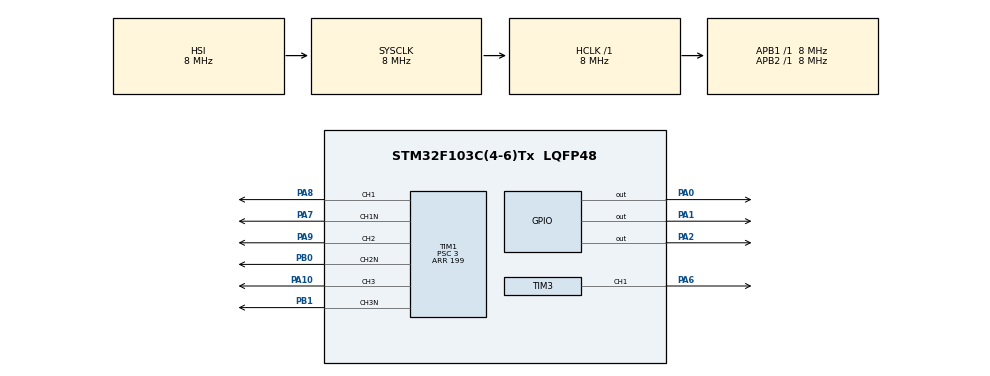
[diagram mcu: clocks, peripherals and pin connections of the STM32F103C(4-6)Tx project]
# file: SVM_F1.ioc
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Mcu.Family=STM32F1
Mcu.Name=STM32F103C(4-6)Tx
Mcu.Package=LQFP48
NVIC.PriorityGroup=NVIC_PRIORITYGROUP_4
PA0-WKUP.Signal=GPIO_Output
PA1.Signal=GPIO_Output
PA10.Signal=S_TIM1_CH3
PA2.Signal=GPIO_Output
PA6.Signal=S_TIM3_CH1
PA7.Mode=PWM Generation1 CH1 CH1N
PA7.Signal=TIM1_CH1N
PA8.Signal=S_TIM1_CH1
PA9.Signal=S_TIM1_CH2
PB0.Mode=PWM Generation2 CH2 CH2N
PB0.Signal=TIM1_CH2N
PB1.Mode=PWM Generation3 CH3 CH3N
PB1.Signal=TIM1_CH3N
ProjectManager.HeapSize=0x200
ProjectManager.StackSize=0x400
ProjectManager.TargetToolchain=TrueSTUDIO
RCC.AHBFreq_Value=8000000
RCC.APB1Freq_Value=8000000
RCC.APB1TimFreq_Value=8000000
RCC.APB2Freq_Value=8000000
RCC.APB2TimFreq_Value=8000000
RCC.HCLKFreq_Value=8000000
RCC.SYSCLKFreq_VALUE=8000000
RCC.USBFreq_Value=8000000
SH.S_TIM1_CH1.0=TIM1_CH1,PWM Generation1 CH1 CH1N
SH.S_TIM1_CH2.0=TIM1_CH2,PWM Generation2 CH2 CH2N
SH.S_TIM1_CH3.0=TIM1_CH3,PWM Generation3 CH3 CH3N
SH.S_TIM3_CH1.0=TIM3_CH1,PWM Generation1 CH1
TIM1.Channel-PWM\ Generation1\ CH1\ CH1N=TIM_CHANNEL_1
TIM1.Channel-PWM\ Generation2\ CH2\ CH2N=TIM_CHANNEL_2
TIM1.Channel-PWM\ Generation3\ CH3\ CH3N=TIM_CHANNEL_3
TIM1.Period=199
TIM1.Prescaler=3
TIM3.Channel-PWM\ Generation1\ CH1=TIM_CHANNEL_1
TIM3.Period=199
TIM3.Prescaler=3
VP_SYS_VS_ND.Mode=No_Debug
VP_TIM1_VS_ClockSourceINT.Mode=Internal
VP_TIM3_VS_ClockSourceINT.Mode=Internal
board=custom

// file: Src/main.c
/**
  ******************************************************************************
  * @file           : main.c
  * @brief          : Main program body
  ******************************************************************************
  ** This notice applies to any and all portions of this file
  * that are not between comment pairs USER CODE BEGIN and
  * USER CODE END. Other portions of this file, whether
  * inserted by the user or by software development tools
  * are owned by their respective copyright owners.
  *
  * COPYRIGHT(c) 2018 STMicroelectronics
  *
  * Redistribution and use in source and binary forms, with or without modification,
  * are permitted provided that the following conditions are met:
  *   1. Redistributions of source code must retain the above copyright notice,
  *      this list of conditions and the following disclaimer.
  *   2. Redistributions in binary form must reproduce the above copyright notice,
  *      this list of conditions and the following disclaimer in the documentation
  *      and/or other materials provided with the distribution.
  *   3. Neither the name of STMicroelectronics nor the names of its contributors
  *      may be used to endorse or promote products derived from this software
  *      without specific prior written permission.
  *
  * THIS SOFTWARE IS PROVIDED BY THE COPYRIGHT HOLDERS AND CONTRIBUTORS "AS IS"
  * AND ANY EXPRESS OR IMPLIED WARRANTIES, INCLUDING, BUT NOT LIMITED TO, THE
  * IMPLIED WARRANTIES OF MERCHANTABILITY AND FITNESS FOR A PARTICULAR PURPOSE ARE
  * DISCLAIMED. IN NO EVENT SHALL THE COPYRIGHT HOLDER OR CONTRIBUTORS BE LIABLE
  * FOR ANY DIRECT, INDIRECT, INCIDENTAL, SPECIAL, EXEMPLARY, OR CONSEQUENTIAL
  * DAMAGES (INCLUDING, BUT NOT LIMITED TO, PROCUREMENT OF SUBSTITUTE GOODS OR
  * SERVICES; LOSS OF USE, DATA, OR PROFITS; OR BUSINESS INTERRUPTION) HOWEVER
  * CAUSED AND ON ANY THEORY OF LIABILITY, WHETHER IN CONTRACT, STRICT LIABILITY,
  * OR TORT (INCLUDING NEGLIGENCE OR OTHERWISE) ARISING IN ANY WAY OUT OF THE USE
  * OF THIS SOFTWARE, EVEN IF ADVISED OF THE POSSIBILITY OF SUCH DAMAGE.
  *
  ******************************************************************************
  */
#include "main.h"
#include "stm32f1xx_hal.h"
#include "tim.h"
#include "gpio.h"

/* USER CODE BEGIN PV */
/* Private variables ---------------------------------------------------------*/

/* USER CODE END PV */

void SystemClock_Config(void);

/* USER CODE BEGIN PFP */
/* Private function prototypes -----------------------------------------------*/

/* USER CODE END PFP */

int main(void)
{

  /* MCU Configuration----------------------------------------------------------*/

  /* Reset of all peripherals, Initializes the Flash interface and the Systick. */
  HAL_Init();

  /* Configure the system clock */
  SystemClock_Config();

  /* Initialize all configured peripherals */
  MX_GPIO_Init();
  MX_TIM1_Init();
  MX_TIM3_Init();
  /* USER CODE BEGIN 2 */
  HAL_TIM_Base_Start_IT(&htim1);

  /* USER CODE END 2 */

  /* Infinite loop */
  /* USER CODE BEGIN WHILE */
  while (1)
  {
	  __HAL_TIM_SET_COMPARE(&htim1, TIM_CHANNEL_1, 100);
	  HAL_GPIO_WritePin( GPIOA, GPIO_PIN_0, 0);
	  HAL_GPIO_TogglePin(GPIOA, GPIO_PIN_1);
	  HAL_Delay(500);
	  HAL_GPIO_WritePin( GPIOA, GPIO_PIN_0, 1);
	  HAL_Delay(500);
  /* USER CODE END WHILE */

  }

}

void SystemClock_Config(void)
{

  RCC_OscInitTypeDef RCC_OscInitStruct;
  RCC_ClkInitTypeDef RCC_ClkInitStruct;

    /**Initializes the CPU, AHB and APB busses clocks
    */
  RCC_OscInitStruct.OscillatorType = RCC_OSCILLATORTYPE_HSI;
  RCC_OscInitStruct.HSIState = RCC_HSI_ON;
  RCC_OscInitStruct.HSICalibrationValue = 16;
  RCC_OscInitStruct.PLL.PLLState = RCC_PLL_NONE;
  if (HAL_RCC_OscConfig(&RCC_OscInitStruct) != HAL_OK)
  {
    _Error_Handler(__FILE__, __LINE__);
  }

    /**Initializes the CPU, AHB and APB busses clocks
    */
  RCC_ClkInitStruct.ClockType = RCC_CLOCKTYPE_HCLK|RCC_CLOCKTYPE_SYSCLK
                              |RCC_CLOCKTYPE_PCLK1|RCC_CLOCKTYPE_PCLK2;
  RCC_ClkInitStruct.SYSCLKSource = RCC_SYSCLKSOURCE_HSI;
  RCC_ClkInitStruct.AHBCLKDivider = RCC_SYSCLK_DIV1;
  RCC_ClkInitStruct.APB1CLKDivider = RCC_HCLK_DIV1;
  RCC_ClkInitStruct.APB2CLKDivider = RCC_HCLK_DIV1;

  if (HAL_RCC_ClockConfig(&RCC_ClkInitStruct, FLASH_LATENCY_0) != HAL_OK)
  {
    _Error_Handler(__FILE__, __LINE__);
  }

    /**Configure the Systick interrupt time
    */
  HAL_SYSTICK_Config(HAL_RCC_GetHCLKFreq()/1000);

    /**Configure the Systick
    */
  HAL_SYSTICK_CLKSourceConfig(SYSTICK_CLKSOURCE_HCLK);

  /* SysTick_IRQn interrupt configuration */
  HAL_NVIC_SetPriority(SysTick_IRQn, 0, 0);
}

void _Error_Handler(char *file, int line)
{
  while(1)
  {
  }
}

/************************ (C) COPYRIGHT STMicroelectronics *****END OF FILE****/
